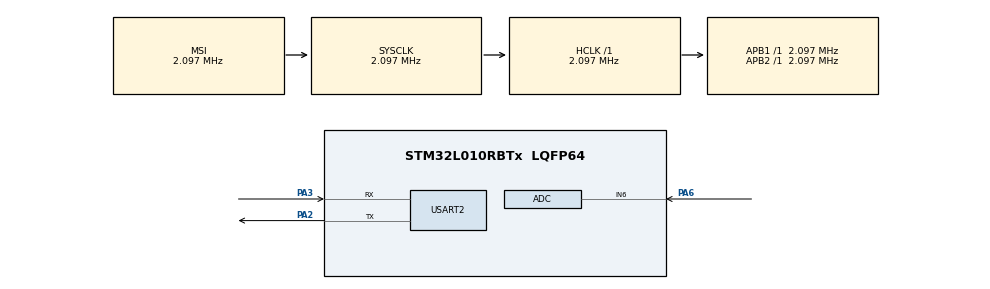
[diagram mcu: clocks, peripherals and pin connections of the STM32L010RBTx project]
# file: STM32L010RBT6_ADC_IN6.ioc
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ADC.ContinuousConvMode=DISABLE
ADC.DMAContinuousRequests=DISABLE
ADC.SamplingTime=ADC_SAMPLETIME_160CYCLES_5
Mcu.Family=STM32L0
Mcu.Name=STM32L010RBTx
Mcu.Package=LQFP64
NVIC.ADC1_IRQn=true\:0\:0\:false\:false\:true\:true\:true\:true
PA2.Mode=Asynchronous
PA2.Signal=USART2_TX
PA3.Mode=Asynchronous
PA3.Signal=USART2_RX
PA6.Mode=IN6
PA6.Signal=ADC_IN6
ProjectManager.HeapSize=0x200
ProjectManager.StackSize=0x400
ProjectManager.TargetToolchain=STM32CubeIDE
RCC.AHBFreq_Value=2097000
RCC.APB1Freq_Value=2097000
RCC.APB1TimFreq_Value=2097000
RCC.APB2Freq_Value=2097000
RCC.APB2TimFreq_Value=2097000
RCC.HSE_VALUE=8000000
RCC.HSI16_VALUE=16000000
RCC.HSI_VALUE=16000000
RCC.LSE_VALUE=32768
RCC.MSI_VALUE=2097000
RCC.SYSCLKFreq_VALUE=2097000
RCC.VCOOutputFreq_Value=48000000
USART2.VirtualMode-Asynchronous=VM_ASYNC
board=custom

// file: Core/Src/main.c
/* USER CODE BEGIN Header */
/* USER CODE END Header */
#include "main.h"

/* USER CODE BEGIN Includes */
#include <stdio.h>
#include <string.h>
/* USER CODE END Includes */

/* USER CODE BEGIN PD */
#define ADC_RESOLUTION 4095.0f
#define VDDA_VOLTAGE   3.0f // Adjust this if your VDDA is different
/* USER CODE END PD */

ADC_HandleTypeDef hadc;

UART_HandleTypeDef huart2;

/* USER CODE BEGIN PV */
char msg[64]; // Global buffer for UART
/* USER CODE END PV */

void SystemClock_Config(void);
static void MX_GPIO_Init(void);
static void MX_ADC_Init(void);
static void MX_USART2_UART_Init(void);
/* USER CODE BEGIN PFP */
void ADC_Select_Channel(uint32_t channel);
uint16_t ADC_Read_Value(void);
void ADC_Print_Single_Channel(uint32_t channel, const char* label);
/* USER CODE END PFP */

int main(void)
{

  /* MCU Configuration--------------------------------------------------------*/

  /* Reset of all peripherals, Initializes the Flash interface and the Systick. */
  HAL_Init();

  /* Configure the system clock */
  SystemClock_Config();

  /* Initialize all configured peripherals */
  MX_GPIO_Init();
  MX_ADC_Init();
  MX_USART2_UART_Init();
  /* USER CODE BEGIN 2 */
  // ADC Calibration
  if (HAL_ADCEx_Calibration_Start(&hadc, ADC_SINGLE_ENDED) != HAL_OK)
  {
      Error_Handler();
  }
  /* USER CODE END 2 */

  /* Infinite loop */
  /* USER CODE BEGIN WHILE */
  while (1)
  {
	 // ADC_Print_Single_Channel(ADC_CHANNEL_4, "IN4");
	 //     HAL_Delay(1000);

	 //     ADC_Print_Single_Channel(ADC_CHANNEL_5, "IN5");
	 //     HAL_Delay(1000);

	      ADC_Print_Single_Channel(ADC_CHANNEL_6, "IN6");
	      HAL_Delay(1000);
  }
    /* USER CODE END WHILE */

}

void SystemClock_Config(void)
{
  RCC_OscInitTypeDef RCC_OscInitStruct = {0};
  RCC_ClkInitTypeDef RCC_ClkInitStruct = {0};
  RCC_PeriphCLKInitTypeDef PeriphClkInit = {0};

  /** Configure the main internal regulator output voltage
  */
  __HAL_PWR_VOLTAGESCALING_CONFIG(PWR_REGULATOR_VOLTAGE_SCALE1);

  /** Initializes the RCC Oscillators according to the specified parameters
  * in the RCC_OscInitTypeDef structure.
  */
  RCC_OscInitStruct.OscillatorType = RCC_OSCILLATORTYPE_MSI;
  RCC_OscInitStruct.MSIState = RCC_MSI_ON;
  RCC_OscInitStruct.MSICalibrationValue = 0;
  RCC_OscInitStruct.MSIClockRange = RCC_MSIRANGE_5;
  RCC_OscInitStruct.PLL.PLLState = RCC_PLL_NONE;
  if (HAL_RCC_OscConfig(&RCC_OscInitStruct) != HAL_OK)
  {
    Error_Handler();
  }

  /** Initializes the CPU, AHB and APB buses clocks
  */
  RCC_ClkInitStruct.ClockType = RCC_CLOCKTYPE_HCLK|RCC_CLOCKTYPE_SYSCLK
                              |RCC_CLOCKTYPE_PCLK1|RCC_CLOCKTYPE_PCLK2;
  RCC_ClkInitStruct.SYSCLKSource = RCC_SYSCLKSOURCE_MSI;
  RCC_ClkInitStruct.AHBCLKDivider = RCC_SYSCLK_DIV1;
  RCC_ClkInitStruct.APB1CLKDivider = RCC_HCLK_DIV1;
  RCC_ClkInitStruct.APB2CLKDivider = RCC_HCLK_DIV1;

  if (HAL_RCC_ClockConfig(&RCC_ClkInitStruct, FLASH_LATENCY_0) != HAL_OK)
  {
    Error_Handler();
  }
  PeriphClkInit.PeriphClockSelection = RCC_PERIPHCLK_USART2;
  PeriphClkInit.Usart2ClockSelection = RCC_USART2CLKSOURCE_PCLK1;
  if (HAL_RCCEx_PeriphCLKConfig(&PeriphClkInit) != HAL_OK)
  {
    Error_Handler();
  }
}

static void MX_ADC_Init(void)
{

  ADC_ChannelConfTypeDef sConfig = {0};

  /** Configure the global features of the ADC (Clock, Resolution, Data Alignment and number of conversion)
  */
  hadc.Instance = ADC1;
  hadc.Init.OversamplingMode = DISABLE;
  hadc.Init.ClockPrescaler = ADC_CLOCK_SYNC_PCLK_DIV1;
  hadc.Init.Resolution = ADC_RESOLUTION_12B;
  hadc.Init.SamplingTime = ADC_SAMPLETIME_160CYCLES_5;
  hadc.Init.ScanConvMode = ADC_SCAN_DIRECTION_FORWARD;
  hadc.Init.DataAlign = ADC_DATAALIGN_RIGHT;
  hadc.Init.ContinuousConvMode = DISABLE;
  hadc.Init.DiscontinuousConvMode = DISABLE;
  hadc.Init.ExternalTrigConvEdge = ADC_EXTERNALTRIGCONVEDGE_NONE;
  hadc.Init.ExternalTrigConv = ADC_SOFTWARE_START;
  hadc.Init.DMAContinuousRequests = DISABLE;
  hadc.Init.EOCSelection = ADC_EOC_SINGLE_CONV;
  hadc.Init.Overrun = ADC_OVR_DATA_PRESERVED;
  hadc.Init.LowPowerAutoWait = DISABLE;
  hadc.Init.LowPowerFrequencyMode = ENABLE;
  hadc.Init.LowPowerAutoPowerOff = DISABLE;
  if (HAL_ADC_Init(&hadc) != HAL_OK)
  {
    Error_Handler();
  }

  /** Configure for the selected ADC regular channel to be converted.
  */
  sConfig.Channel = ADC_CHANNEL_6;
  sConfig.Rank = ADC_RANK_CHANNEL_NUMBER;
  if (HAL_ADC_ConfigChannel(&hadc, &sConfig) != HAL_OK)
  {
    Error_Handler();
  }

}

static void MX_USART2_UART_Init(void)
{

  huart2.Instance = USART2;
  huart2.Init.BaudRate = 115200;
  huart2.Init.WordLength = UART_WORDLENGTH_8B;
  huart2.Init.StopBits = UART_STOPBITS_1;
  huart2.Init.Parity = UART_PARITY_NONE;
  huart2.Init.Mode = UART_MODE_TX_RX;
  huart2.Init.HwFlowCtl = UART_HWCONTROL_NONE;
  huart2.Init.OverSampling = UART_OVERSAMPLING_16;
  huart2.Init.OneBitSampling = UART_ONE_BIT_SAMPLE_DISABLE;
  huart2.AdvancedInit.AdvFeatureInit = UART_ADVFEATURE_NO_INIT;
  if (HAL_UART_Init(&huart2) != HAL_OK)
  {
    Error_Handler();
  }

}

static void MX_GPIO_Init(void)
{

  /* GPIO Ports Clock Enable */
  __HAL_RCC_GPIOA_CLK_ENABLE();

}

/* USER CODE BEGIN 4 */
// Select the ADC channel
void ADC_Select_Channel(uint32_t channel)
{
    ADC_ChannelConfTypeDef sConfig = {0};
    sConfig.Channel = channel;
    sConfig.Rank = ADC_RANK_CHANNEL_NUMBER;
    if (HAL_ADC_ConfigChannel(&hadc, &sConfig) != HAL_OK)
    {
        Error_Handler();
    }
    // Dummy reads to stabilize after channel switch
    for (int i = 0; i < 2; i++) {
        HAL_ADC_Start(&hadc);
        HAL_ADC_PollForConversion(&hadc, HAL_MAX_DELAY);
        HAL_ADC_GetValue(&hadc);
        HAL_ADC_Stop(&hadc);
    }
}

// Read ADC value for the selected channel
uint16_t ADC_Read_Value(void)
{
	 uint32_t sum = 0;
	    const uint8_t samples = 8;

	    for (uint8_t i = 0; i < samples; i++) {
	        HAL_ADC_Start(&hadc);
	        HAL_ADC_PollForConversion(&hadc, HAL_MAX_DELAY);
	        sum += HAL_ADC_GetValue(&hadc);
	        HAL_ADC_Stop(&hadc);
	        HAL_Delay(2);  // small delay to allow voltage to settle
	    }

	    return (uint16_t)(sum / samples);
}
// Print ADC values for single channel
void ADC_Print_Single_Channel(uint32_t channel, const char* label)
{
    char msg[64];
    float voltage;

    ADC_Select_Channel(channel);
    uint16_t raw = ADC_Read_Value();
    voltage = (raw / ADC_RESOLUTION) * 3.0f;

    snprintf(msg, sizeof(msg), "%s: %.3f V\r\n", label, voltage);
    HAL_UART_Transmit(&huart2, (uint8_t*)msg, strlen(msg), HAL_MAX_DELAY);
}
/* USER CODE END 4 */

void Error_Handler(void)
{
}
